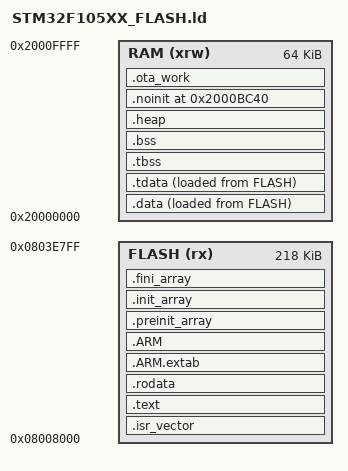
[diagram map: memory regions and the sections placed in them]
/*
******************************************************************************
**

**  File        : LinkerScript.ld
**
**  Author		: STM32CubeMX
**
**  Abstract    : Linker script for STM32F105RCTx series
**                256Kbytes FLASH and 64Kbytes RAM
**
**                Set heap size, stack size and stack location according
**                to application requirements.
**
**                Set memory bank area and size if external memory is used.
**
**  Target      : STMicroelectronics STM32
**
**  Distribution: The file is distributed “as is,” without any warranty
**                of any kind.
**
*****************************************************************************
** @attention
**
** <h2><center>&copy; COPYRIGHT(c) 2025 STMicroelectronics</center></h2>
**
** Redistribution and use in source and binary forms, with or without modification,
** are permitted provided that the following conditions are met:
**   1. Redistributions of source code must retain the above copyright notice,
**      this list of conditions and the following disclaimer.
**   2. Redistributions in binary form must reproduce the above copyright notice,
**      this list of conditions and the following disclaimer in the documentation
**      and/or other materials provided with the distribution.
**   3. Neither the name of STMicroelectronics nor the names of its contributors
**      may be used to endorse or promote products derived from this software
**      without specific prior written permission.
**
** THIS SOFTWARE IS PROVIDED BY THE COPYRIGHT HOLDERS AND CONTRIBUTORS "AS IS"
** AND ANY EXPRESS OR IMPLIED WARRANTIES, INCLUDING, BUT NOT LIMITED TO, THE
** IMPLIED WARRANTIES OF MERCHANTABILITY AND FITNESS FOR A PARTICULAR PURPOSE ARE
** DISCLAIMED. IN NO EVENT SHALL THE COPYRIGHT HOLDER OR CONTRIBUTORS BE LIABLE
** FOR ANY DIRECT, INDIRECT, INCIDENTAL, SPECIAL, EXEMPLARY, OR CONSEQUENTIAL
** DAMAGES (INCLUDING, BUT NOT LIMITED TO, PROCUREMENT OF SUBSTITUTE GOODS OR
** SERVICES; LOSS OF USE, DATA, OR PROFITS; OR BUSINESS INTERRUPTION) HOWEVER
** CAUSED AND ON ANY THEORY OF LIABILITY, WHETHER IN CONTRACT, STRICT LIABILITY,
** OR TORT (INCLUDING NEGLIGENCE OR OTHERWISE) ARISING IN ANY WAY OUT OF THE USE
** OF THIS SOFTWARE, EVEN IF ADVISED OF THE POSSIBILITY OF SUCH DAMAGE.
**
*****************************************************************************
*/

/* Entry Point */
ENTRY(Reset_Handler)

/* Specify the memory areas */
MEMORY
{
RAM (xrw)      : ORIGIN = 0x20000000, LENGTH = 64K
/* Boot V2 reserves 0x0803E800..0x0803F7FF for redundant state records. */
FLASH (rx)      : ORIGIN = 0x08008000, LENGTH = 0x36800
}

/* Highest address of the user mode stack */
_estack = ORIGIN(RAM) + LENGTH(RAM);    /* end of RAM */
_sstack = _estack - _Min_Stack_Size;
/* Generate a link error if heap and stack don't fit into RAM */
_Min_Heap_Size = 0x2000;      /* required amount of heap  */
_Min_Stack_Size = 0x1000; /* required amount of stack */

/* Define output sections */
SECTIONS
{
  /* The startup code goes first into FLASH */
  .isr_vector :
  {
    . = ALIGN(4);
    KEEP(*(.isr_vector)) /* Startup code */
    . = ALIGN(4);
  } >FLASH

  /* The program code and other data goes into FLASH */
  .text :
  {
    . = ALIGN(4);
    *(.text)           /* .text sections (code) */
    *(.text*)          /* .text* sections (code) */
    *(.glue_7)         /* glue arm to thumb code */
    *(.glue_7t)        /* glue thumb to arm code */
    *(.eh_frame)

    KEEP (*(.init))
    KEEP (*(.fini))

    . = ALIGN(4);
    _etext = .;        /* define a global symbols at end of code */
  } >FLASH

  /* Constant data goes into FLASH */
  .rodata :
  {
    . = ALIGN(4);
    *(.rodata)         /* .rodata sections (constants, strings, etc.) */
    *(.rodata*)        /* .rodata* sections (constants, strings, etc.) */
    . = ALIGN(4);
  } >FLASH

  .ARM.extab (READONLY) : /* The "READONLY" keyword is only supported in GCC11 and later, remove it if using GCC10 or earlier. */
  {
    . = ALIGN(4);
    *(.ARM.extab* .gnu.linkonce.armextab.*)
    . = ALIGN(4);
  } >FLASH

  .ARM (READONLY) : /* The "READONLY" keyword is only supported in GCC11 and later, remove it if using GCC10 or earlier. */
  {
    . = ALIGN(4);
    __exidx_start = .;
    *(.ARM.exidx*)
    __exidx_end = .;
    . = ALIGN(4);
  } >FLASH

  .preinit_array (READONLY) : /* The "READONLY" keyword is only supported in GCC11 and later, remove it if using GCC10 or earlier. */
  {
    . = ALIGN(4);
    PROVIDE_HIDDEN (__preinit_array_start = .);
    KEEP (*(.preinit_array*))
    PROVIDE_HIDDEN (__preinit_array_end = .);
    . = ALIGN(4);
  } >FLASH

  .init_array (READONLY) : /* The "READONLY" keyword is only supported in GCC11 and later, remove it if using GCC10 or earlier. */
  {
    . = ALIGN(4);
    PROVIDE_HIDDEN (__init_array_start = .);
    KEEP (*(SORT(.init_array.*)))
    KEEP (*(.init_array*))
    PROVIDE_HIDDEN (__init_array_end = .);
    . = ALIGN(4);
  } >FLASH

  .fini_array (READONLY) : /* The "READONLY" keyword is only supported in GCC11 and later, remove it if using GCC10 or earlier. */
  {
    . = ALIGN(4);
    PROVIDE_HIDDEN (__fini_array_start = .);
    KEEP (*(SORT(.fini_array.*)))
    KEEP (*(.fini_array*))
    PROVIDE_HIDDEN (__fini_array_end = .);
    . = ALIGN(4);
  } >FLASH

  /* Used by the App to seed a Boot V2 stable record on factory images. */
  __app_image_end = LOADADDR(.data) + SIZEOF(.data);

  /* used by the startup to initialize data */
  _sidata = LOADADDR(.data);

  /* Initialized data sections goes into RAM, load LMA copy after code */
  .data :
  {
    . = ALIGN(4);
    _sdata = .;        /* create a global symbol at data start */
    *(.data)           /* .data sections */
    *(.data*)          /* .data* sections */
    *(.RamFunc)        /* .RamFunc sections */
    *(.RamFunc*)       /* .RamFunc* sections */

    . = ALIGN(4);
  } >RAM AT> FLASH

 /* Initialized TLS data section */
  .tdata : ALIGN(4)
  {
    *(.tdata .tdata.* .gnu.linkonce.td.*)
    . = ALIGN(4);
    _edata = .;        /* define a global symbol at data end */
    PROVIDE(__data_end = .);
    PROVIDE(__tdata_end = .);
  } >RAM AT> FLASH

  PROVIDE( __tdata_start = ADDR(.tdata) );
  PROVIDE( __tdata_size = __tdata_end - __tdata_start );

  PROVIDE( __data_start = ADDR(.data) );
  PROVIDE( __data_size = __data_end - __data_start );

  PROVIDE( __tdata_source = LOADADDR(.tdata) );
  PROVIDE( __tdata_source_end = LOADADDR(.tdata) + SIZEOF(.tdata) );
  PROVIDE( __tdata_source_size = __tdata_source_end - __tdata_source );

  PROVIDE( __data_source = LOADADDR(.data) );
  PROVIDE( __data_source_end = __tdata_source_end );
  PROVIDE( __data_source_size = __data_source_end - __data_source );
  /* Uninitialized data section */
  .tbss (NOLOAD) : ALIGN(4)
  {
     /* This is used by the startup in order to initialize the .bss secion */
    _sbss = .;         /* define a global symbol at bss start */
    __bss_start__ = _sbss;
    *(.tbss .tbss.*)
    . = ALIGN(4);
    PROVIDE( __tbss_end = . );
  } >RAM

  PROVIDE( __tbss_start = ADDR(.tbss) );
  PROVIDE( __tbss_size = __tbss_end - __tbss_start );
  PROVIDE( __tbss_offset = ADDR(.tbss) - ADDR(.tdata) );

  PROVIDE( __tls_base = __tdata_start );
  PROVIDE( __tls_end = __tbss_end );
  PROVIDE( __tls_size = __tls_end - __tls_base );
  PROVIDE( __tls_align = MAX(ALIGNOF(.tdata), ALIGNOF(.tbss)) );
  PROVIDE( __tls_size_align = (__tls_size + __tls_align - 1) & ~(__tls_align - 1) );
  PROVIDE( __arm32_tls_tcb_offset = MAX(8, __tls_align) );
  PROVIDE( __arm64_tls_tcb_offset = MAX(16, __tls_align) );

  .bss (NOLOAD) : ALIGN(4)
  {
    *(.bss)
    *(.bss*)
    *(COMMON)

      . = ALIGN(4);
    _ebss = .;         /* define a global symbol at bss end */
    __bss_end__ = _ebss;
      PROVIDE( __bss_end = .);
  } >RAM
  PROVIDE( __non_tls_bss_start = ADDR(.bss) );

  /* Keep the reset-retained mailbox address compatible with Boot 2.2.0, but
     use the otherwise empty range before it as the bounded newlib heap. */
  .heap (NOLOAD) : ALIGN(8)
  {
    PROVIDE (end = .);
    PROVIDE (_end = .);
    __heap_start = .;
    . = . + _Min_Heap_Size;
    __heap_min_end = .;
  } >RAM
  __heap_limit = 0x2000BC40;

  .noinit 0x2000BC40 (NOLOAD) : ALIGN(4)
  {
    *(.noinit)
  } >RAM

  .ota_work (NOLOAD) : ALIGN(4)
  {
    *(.ota_work)
  } >RAM

  PROVIDE( __bss_start = __tbss_start );
  PROVIDE( __bss_size = __bss_end - __bss_start );

  ASSERT(_ebss <= __heap_start, "App BSS overlaps dedicated heap")
  ASSERT(__heap_min_end <= __heap_limit, "App minimum heap overlaps Boot/App fault mailbox")
  ASSERT(ADDR(.noinit) == 0x2000BC40, "Boot/App fault mailbox address mismatch")
  ASSERT((ADDR(.ota_work) + SIZEOF(.ota_work)) <= _sstack, "App OTA workspace leaves less than minimum stack")



  /* Remove information from the standard libraries */
  /DISCARD/ :
  {
    libc.a:* ( * )
    libm.a:* ( * )
    libgcc.a:* ( * )
  }

}
